VERSION ""

NS_ :

BS_:

BU_: IMU VCU

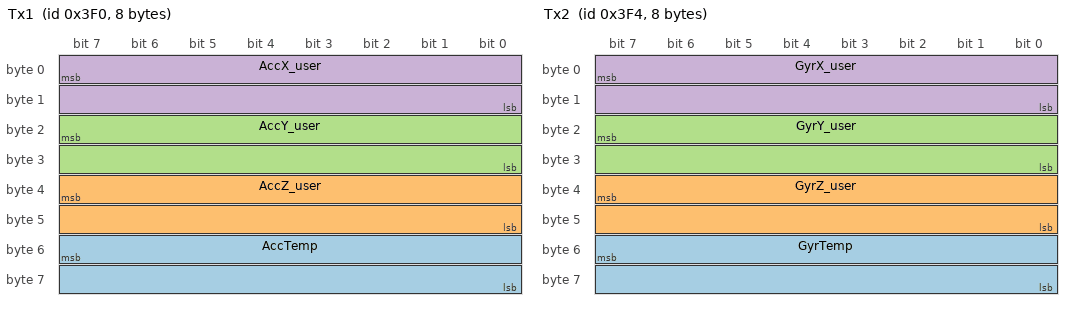
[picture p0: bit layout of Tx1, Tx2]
BO_ 1008 Tx1: 8 IMU
 SG_ AccTemp : 55|16@0- (0.1,0) [-3276.8|3276.7] "°C" Vector__XXX
 SG_ AccZ_user : 39|16@0- (0.001,0) [-32.768|32.767] "g" Vector__XXX
 SG_ AccY_user : 23|16@0- (0.001,0) [-32.768|32.767] "g" Vector__XXX
 SG_ AccX_user : 7|16@0- (0.001,0) [-32.768|32.767] "g" Vector__XXX

BO_ 1012 Tx2: 8 IMU
 SG_ GyrTemp : 55|16@0- (0.1,0) [-3276.8|3276.7] "°C" Vector__XXX
 SG_ GyrZ_user : 39|16@0- (0.01,0) [-327.68|327.67] "°/s" Vector__XXX
 SG_ GyrY_user : 23|16@0- (0.01,0) [-327.68|327.67] "°/s" Vector__XXX
 SG_ GyrX_user : 7|16@0- (0.01,0) [-327.68|327.67] "°/s" Vector__XXX

BA_DEF_  "Baudrate" INT 0 1000000;
BA_DEF_  "BusType" STRING ;
BA_DEF_  "DBName" STRING ;
BA_DEF_ SG_  "GenSigSendType" ENUM  "Cyclic","OnWrite","OnWriteWithRepetition","OnChange","OnChangeWithRepetition","IfActive","IfActiveWithRepetition";
BA_DEF_ BO_  "GenMsgCycleTimeFast" INT 2 50000;
BA_DEF_ BO_  "GenMsgSendType" ENUM  "Cyclic","Spontaneous","NotUsed","NotUsed","NotUsed","NotUsed","NotUsed","IfActive","NoMsgSendType","NotUsed";
BA_DEF_ BO_  "GenMsgCycleTime" INT 0 1000;
BA_DEF_ BO_  "GenMsgILSupport" ENUM  "No","Yes";
BA_DEF_ BU_  "ILUsed" ENUM  "No","Yes";
BA_DEF_DEF_  "Baudrate" 1000000;
BA_DEF_DEF_  "BusType" "CAN";
BA_DEF_DEF_  "DBName" "";
BA_DEF_DEF_  "GenSigSendType" "Cyclic";
BA_DEF_DEF_  "GenMsgCycleTimeFast" 100;
BA_DEF_DEF_  "GenMsgSendType" "Cyclic";
BA_DEF_DEF_  "GenMsgCycleTime" 0;
BA_DEF_DEF_  "GenMsgILSupport" "Yes";
BA_DEF_DEF_  "ILUsed" "Yes";
BA_ "DBName" "IMU";
BA_ "GenMsgCycleTime" BO_ 1008 2;
BA_ "GenMsgCycleTime" BO_ 1012 2;
